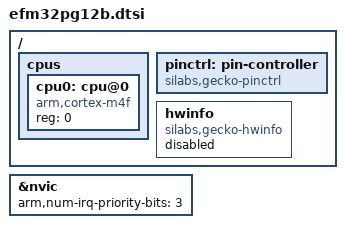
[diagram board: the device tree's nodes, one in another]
/*
 * Copyright (c) 2018 Christian Taedcke <hacking@taedcke.com>
 * Copyright (c) 2019 Lemonbeat GmbH
 *
 * SPDX-License-Identifier: Apache-2.0
 */

#include <silabs/efm32_jg_pg_12b.dtsi>

/ {
	cpus {
		cpu0: cpu@0 {
			compatible = "arm,cortex-m4f";
			reg = <0>;
		};
	};
};

/ {
	pinctrl: pin-controller {
		/* Pin controller is a "virtual" device since SiLabs SoCs do pin
		 * control in a distributed way (GPIO registers and PSEL
		 * registers on each peripheral).
		 */
		compatible = "silabs,gecko-pinctrl";
	};

	hwinfo: hwinfo {
		compatible = "silabs,gecko-hwinfo";
		status = "disabled";
	};

};

&nvic {
	arm,num-irq-priority-bits = <3>;
};
